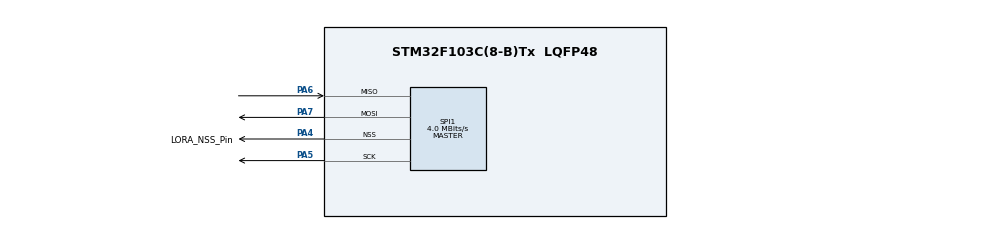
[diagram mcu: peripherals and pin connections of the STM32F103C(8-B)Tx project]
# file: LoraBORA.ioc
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Mcu.Family=STM32F1
Mcu.Name=STM32F103C(8-B)Tx
Mcu.Package=LQFP48
NVIC.PriorityGroup=NVIC_PRIORITYGROUP_4
PA4.GPIO_Label=LORA_NSS_Pin
PA4.Mode=NSS_Signal_Hard_Output
PA4.Signal=SPI1_NSS
PA5.Mode=Full_Duplex_Master
PA5.Signal=SPI1_SCK
PA6.Mode=Full_Duplex_Master
PA6.Signal=SPI1_MISO
PA7.Mode=Full_Duplex_Master
PA7.Signal=SPI1_MOSI
ProjectManager.HeapSize=0x200
ProjectManager.StackSize=0x400
ProjectManager.TargetToolchain=STM32CubeIDE
RCC.APB1Freq_Value=8000000
RCC.APB2Freq_Value=8000000
SPI1.CalculateBaudRate=4.0 MBits/s
SPI1.Direction=SPI_DIRECTION_2LINES
SPI1.Mode=SPI_MODE_MASTER
SPI1.VirtualNSS=VM_NSSHARD
SPI1.VirtualType=VM_MASTER
VP_SYS_VS_ND.Mode=No_Debug
board=custom

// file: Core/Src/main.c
/* USER CODE BEGIN Header */
/**
  ******************************************************************************
  * @file           : main.c
  * @brief          : Main program body
  ******************************************************************************
  * @attention
  *
  * <h2><center>&copy; Copyright (c) 2023 STMicroelectronics.
  * All rights reserved.</center></h2>
  *
  * This software component is licensed by ST under BSD 3-Clause license,
  * the "License"; You may not use this file except in compliance with the
  * License. You may obtain a copy of the License at:
  *                        opensource.org/licenses/BSD-3-Clause
  *
  ******************************************************************************
  */
/* USER CODE END Header */
#include "main.h"
#include "spi.h"
#include "gpio.h"

/* USER CODE BEGIN Includes */
#include "lora_sx1276.h"

/* USER CODE END Includes */

/* USER CODE BEGIN PD */
#define LORA_NSS_Pin GPIO_PIN_4
#define LORA_NSS_GPIO_Port GPIOA
/* USER CODE END PD */

void SystemClock_Config(void);

int main(void)
{

  /* MCU Configuration--------------------------------------------------------*/

  /* Reset of all peripherals, Initializes the Flash interface and the Systick. */
  HAL_Init();

  /* USER CODE BEGIN Init */

  lora_sx1276 lora;

  // SX1276 compatible module connected to SPI1, NSS pin connected to GPIO with label LORA_NSS
  uint8_t res = lora_init(&lora, &hspi1, LORA_NSS_GPIO_Port, LORA_NSS_Pin, LORA_BASE_FREQUENCY_US);
  if (res != LORA_OK) {
    // Initialization failed
  }

  /* USER CODE END Init */

  /* Configure the system clock */
  SystemClock_Config();

  /* Initialize all configured peripherals */
  MX_GPIO_Init();
  MX_SPI1_Init();

  /* Infinite loop */
  while (1)
  {
	  // Send packet can be as simple as
	  uint8_t res = lora_send_packet(&lora, (uint8_t *)"test", 4);
	  if (res != LORA_OK) {
	    // Send failed
	  }
  }
}

void SystemClock_Config(void)
{
  RCC_OscInitTypeDef RCC_OscInitStruct = {0};
  RCC_ClkInitTypeDef RCC_ClkInitStruct = {0};

  /** Initializes the RCC Oscillators according to the specified parameters
  * in the RCC_OscInitTypeDef structure.
  */
  RCC_OscInitStruct.OscillatorType = RCC_OSCILLATORTYPE_HSI;
  RCC_OscInitStruct.HSIState = RCC_HSI_ON;
  RCC_OscInitStruct.HSICalibrationValue = RCC_HSICALIBRATION_DEFAULT;
  RCC_OscInitStruct.PLL.PLLState = RCC_PLL_NONE;
  if (HAL_RCC_OscConfig(&RCC_OscInitStruct) != HAL_OK)
  {
    Error_Handler();
  }
  /** Initializes the CPU, AHB and APB buses clocks
  */
  RCC_ClkInitStruct.ClockType = RCC_CLOCKTYPE_HCLK|RCC_CLOCKTYPE_SYSCLK
                              |RCC_CLOCKTYPE_PCLK1|RCC_CLOCKTYPE_PCLK2;
  RCC_ClkInitStruct.SYSCLKSource = RCC_SYSCLKSOURCE_HSI;
  RCC_ClkInitStruct.AHBCLKDivider = RCC_SYSCLK_DIV1;
  RCC_ClkInitStruct.APB1CLKDivider = RCC_HCLK_DIV1;
  RCC_ClkInitStruct.APB2CLKDivider = RCC_HCLK_DIV1;

  if (HAL_RCC_ClockConfig(&RCC_ClkInitStruct, FLASH_LATENCY_0) != HAL_OK)
  {
    Error_Handler();
  }
}

void Error_Handler(void)
{
  __disable_irq();
  while (1)
  {
  }
}

/************************ (C) COPYRIGHT STMicroelectronics *****END OF FILE****/
